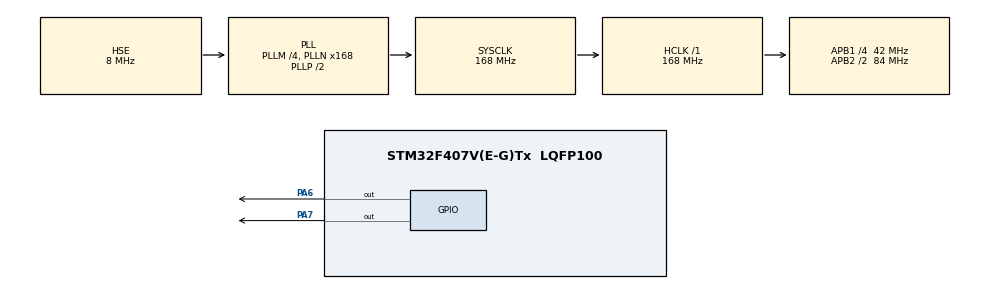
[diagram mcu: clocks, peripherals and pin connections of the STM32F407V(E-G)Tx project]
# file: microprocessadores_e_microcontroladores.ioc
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Mcu.Family=STM32F4
Mcu.Name=STM32F407V(E-G)Tx
Mcu.Package=LQFP100
NVIC.PriorityGroup=NVIC_PRIORITYGROUP_4
PA6.Signal=GPIO_Output
PA7.Signal=GPIO_Output
PH0-OSC_IN.Mode=HSE-External-Oscillator
PH0-OSC_IN.Signal=RCC_OSC_IN
PH1-OSC_OUT.Mode=HSE-External-Oscillator
PH1-OSC_OUT.Signal=RCC_OSC_OUT
ProjectManager.HeapSize=0x200
ProjectManager.StackSize=0x400
ProjectManager.TargetToolchain=STM32CubeIDE
RCC.48MHZClocksFreq_Value=84000000
RCC.AHBFreq_Value=168000000
RCC.APB1CLKDivider=RCC_HCLK_DIV4
RCC.APB1Freq_Value=42000000
RCC.APB1TimFreq_Value=84000000
RCC.APB2CLKDivider=RCC_HCLK_DIV2
RCC.APB2Freq_Value=84000000
RCC.APB2TimFreq_Value=168000000
RCC.CortexFreq_Value=168000000
RCC.HCLKFreq_Value=168000000
RCC.HSE_VALUE=8000000
RCC.HSI_VALUE=16000000
RCC.LSE_VALUE=32768
RCC.PLLM=4
RCC.PLLN=168
RCC.PLLSourceVirtual=RCC_PLLSOURCE_HSE
RCC.SYSCLKFreq_VALUE=168000000
RCC.SYSCLKSource=RCC_SYSCLKSOURCE_PLLCLK
RCC.VCOOutputFreq_Value=336000000
board=custom

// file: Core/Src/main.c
/* USER CODE BEGIN Header */
/**
  ******************************************************************************
  * @file           : main.c
  * @brief          : Main program body
  ******************************************************************************
  * @attention
  *
  * Copyright (c) 2025 STMicroelectronics.
  * All rights reserved.
  *
  * This software is licensed under terms that can be found in the LICENSE file
  * in the root directory of this software component.
  * If no LICENSE file comes with this software, it is provided AS-IS.
  *
  ******************************************************************************
  */
/* USER CODE END Header */
#include "main.h"

/* USER CODE BEGIN Includes */
#include "Utility.h"
/* USER CODE END Includes */

void SystemClock_Config(void);
static void MX_GPIO_Init(void);

int main(void)
{

  /* MCU Configuration--------------------------------------------------------*/

  /* Reset of all peripherals, Initializes the Flash interface and the Systick. */
  HAL_Init();

  /* Configure the system clock */
  SystemClock_Config();

  /* Initialize all configured peripherals */
  MX_GPIO_Init();
  /* USER CODE BEGIN 2 */
  //Utility_Init();

//  FUNÇÃO ALTERNATIVA PARA PA8
//  GPIO_Pin_Mode(GPIOA, PIN_8, ALTERNATE);
//  GPIOA->AFR[1] |= 0b0001;

//  FUNÇÃO ALTERNATIVA PARA PA5
//    GPIO_Pin_Mode(GPIOA, PIN_5, ALTERNATE);
//    GPIO_Alternate_Function(GPIOA, PIN_5, AF1);

  // |= Faz um or/ou bit a bit, mantém os bits intactos e modifica apenas
  // os bits manipulados, que no caso vão ser os bits 12 e 13

  // GPIOA->MODER |= 0b01 << 12;

  // Habilitando clock do GPIOA
  // RCC->AHB1ENR |= 1;
  // Ou então
  //RCC->AHB1ENR |= RCC_AHB1ENR_GPIOAEN;

  // Forma segura de setar bits
  // Atribui o o inverso dos bits 1 e 1 para o pino 2
  //GPIOA->MODER &= ~(0b11 << 12);
  // Define o pino 6 como saída
  //GPIOA->MODER |= 0b01 << 12;

  // incorreto fazer apenas |= 0b01

  // PINOS COMO ENTRADA DIGITAL
  //Utility_Init();
  //GPIO_Clock_Enable(GPIOA);
//GPIO_PIN_Mode(GPIOA, PIN_0, INPUT);

  /* USER CODE END 2 */

  /* Infinite loop */
  /* USER CODE BEGIN WHILE */
  while (1)
  {
//	  GPIOA->ODR |= 1 << 6;
//	  HAL_Delay(1000);
//	  GPIOA->ODR &= ~(1 << 6);
//	  HAL_Delay(1000);

//	  HAL_Delay(1000);
//	  GPIOA->ODR &= ~(1 << 2);
//	  GPIOE->ODR &= ~(1 << 8);
//	  HAL_Delay(100);
//	  GPIOA->ODR |= 1 << 2;
//	  GPIOE->ODR |= 1 << 8;
//	  HAL_Delay(100);
//	  GPIOA->ODR &= ~(1 << 2);
//	  GPIOE->ODR &= ~(1 << 8);
//	  HAL_Delay(100);
//	  GPIOE->ODR |= 1 << 8;
//	  GPIOA->ODR |= 1 << 2;
//	  HAL_Delay(100);
//	  GPIOA->ODR &= ~(1 << 2);
//	  GPIOE->ODR &= ~(1 << 8);

	  HAL_GPIO_WritePin(GPIOA, GPIO_PIN_6, GPIO_PIN_RESET);
	  HAL_GPIO_WritePin(GPIOA, GPIO_PIN_7, GPIO_PIN_RESET);

// 			PWM
//	    for (int i = 0; i <= 2000; i++) {
//	        HAL_GPIO_WritePin(GPIOA, GPIO_PIN_7, GPIO_PIN_RESET); // LIGA
//	        Delay_us(i);
//	        HAL_GPIO_WritePin(GPIOA, GPIO_PIN_7, GPIO_PIN_SET);   // DESLIGA
//	        Delay_us(2000 - i);
//	    }
//
//	    for (int i = 2000; i >= 0; i--) {
//	        HAL_GPIO_WritePin(GPIOA, GPIO_PIN_7, GPIO_PIN_RESET); // LIGA
//	        Delay_us(i);
//	        HAL_GPIO_WritePin(GPIOA, GPIO_PIN_7, GPIO_PIN_SET);   // DESLIGA
//	        Delay_us(2000 - i);
//	    }

	  // ENTRADA DIGITAL NO PE3
//	  if (!HAL_GPIO_ReadPin(GPIOE, GPIO_PIN_3)){
//		  HAL_GPIO_WritePin(GPIOA, GPIO_PIN_6, GPIO_PIN_RESET);
//	  } else{
//		  HAL_GPIO_WritePin(GPIOA, GPIO_PIN_6, GPIO_PIN_SET);
//	  }

    /* USER CODE END WHILE */

  }
}

void SystemClock_Config(void)
{
  RCC_OscInitTypeDef RCC_OscInitStruct = {0};
  RCC_ClkInitTypeDef RCC_ClkInitStruct = {0};

  /** Configure the main internal regulator output voltage
  */
  __HAL_RCC_PWR_CLK_ENABLE();
  __HAL_PWR_VOLTAGESCALING_CONFIG(PWR_REGULATOR_VOLTAGE_SCALE1);

  /** Initializes the RCC Oscillators according to the specified parameters
  * in the RCC_OscInitTypeDef structure.
  */
  RCC_OscInitStruct.OscillatorType = RCC_OSCILLATORTYPE_HSE;
  RCC_OscInitStruct.HSEState = RCC_HSE_ON;
  RCC_OscInitStruct.PLL.PLLState = RCC_PLL_ON;
  RCC_OscInitStruct.PLL.PLLSource = RCC_PLLSOURCE_HSE;
  RCC_OscInitStruct.PLL.PLLM = 4;
  RCC_OscInitStruct.PLL.PLLN = 168;
  RCC_OscInitStruct.PLL.PLLP = RCC_PLLP_DIV2;
  RCC_OscInitStruct.PLL.PLLQ = 4;
  if (HAL_RCC_OscConfig(&RCC_OscInitStruct) != HAL_OK)
  {
    Error_Handler();
  }

  /** Initializes the CPU, AHB and APB buses clocks
  */
  RCC_ClkInitStruct.ClockType = RCC_CLOCKTYPE_HCLK|RCC_CLOCKTYPE_SYSCLK
                              |RCC_CLOCKTYPE_PCLK1|RCC_CLOCKTYPE_PCLK2;
  RCC_ClkInitStruct.SYSCLKSource = RCC_SYSCLKSOURCE_PLLCLK;
  RCC_ClkInitStruct.AHBCLKDivider = RCC_SYSCLK_DIV1;
  RCC_ClkInitStruct.APB1CLKDivider = RCC_HCLK_DIV4;
  RCC_ClkInitStruct.APB2CLKDivider = RCC_HCLK_DIV2;

  if (HAL_RCC_ClockConfig(&RCC_ClkInitStruct, FLASH_LATENCY_5) != HAL_OK)
  {
    Error_Handler();
  }
}

static void MX_GPIO_Init(void)
{
  GPIO_InitTypeDef GPIO_InitStruct = {0};

  /* GPIO Ports Clock Enable */
  __HAL_RCC_GPIOH_CLK_ENABLE();
  __HAL_RCC_GPIOA_CLK_ENABLE();

  /*Configure GPIO pin Output Level */
  HAL_GPIO_WritePin(GPIOA, GPIO_PIN_6|GPIO_PIN_7, GPIO_PIN_RESET);

  /*Configure GPIO pins : PA6 PA7 */
  GPIO_InitStruct.Pin = GPIO_PIN_6|GPIO_PIN_7;
  GPIO_InitStruct.Mode = GPIO_MODE_OUTPUT_PP;
  GPIO_InitStruct.Pull = GPIO_NOPULL;
  GPIO_InitStruct.Speed = GPIO_SPEED_FREQ_LOW;
  HAL_GPIO_Init(GPIOA, &GPIO_InitStruct);

}

void Error_Handler(void)
{
  __disable_irq();
  while (1)
  {
  }
}
